# ICSSM0_COMMON_0_RAT_SLICE0_CFG register map
Vendor: Texas Instruments
Peripheral module from a debugger description file (folder am62x).
Registers are 32-bit, read-only, reset 0x0 unless marked. A register's access mark holds for its fields unless they carry their own. Offsets are as the file gives them; lines under a group give offsets from that group; [hi:lo] are bit positions; {n}, {i} and the like mark numbered series; 'fields as' and 'values as' point back to an identical list; <NAME> marks a mode.

## ICSSM0_COMMON_0_RAT_SLICE0_CFG
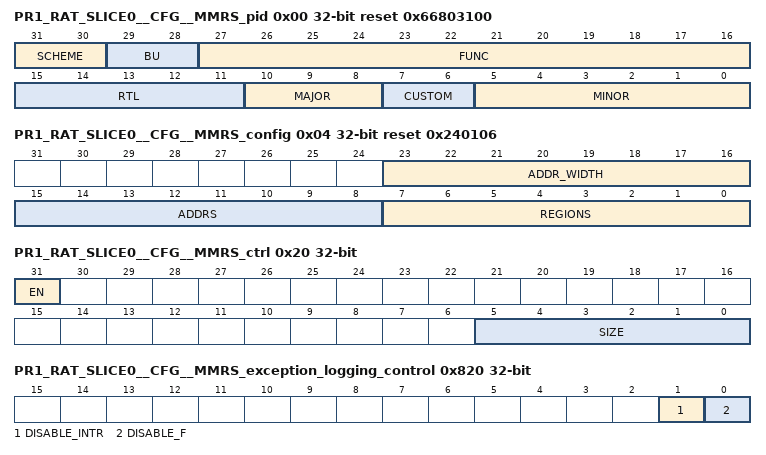
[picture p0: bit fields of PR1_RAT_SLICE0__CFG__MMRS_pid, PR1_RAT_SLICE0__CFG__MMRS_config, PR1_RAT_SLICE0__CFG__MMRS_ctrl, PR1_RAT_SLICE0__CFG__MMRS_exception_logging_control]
0x00 PR1_RAT_SLICE0__CFG__MMRS_pid reset 0x66803100
  [31:30] SCHEME — PID register scheme
  [29:28] BU — Business Unit: 10 = Processors
  [27:16] FUNC — Module ID
  [15:11] RTL — RTL revision. Will vary depending on release.
  [10:8] MAJOR — Major revision
  [7:6] CUSTOM
  [5:0] MINOR — Minor revision
0x04 PR1_RAT_SLICE0__CFG__MMRS_config reset 0x240106
  [23:16] ADDR_WIDTH — Number of address bits
  [15:8] ADDRS — Number of addresses
  [7:0] REGIONS — Number of regions
0x20 PR1_RAT_SLICE0__CFG__MMRS_ctrl rw
  [31] EN — Enable for the Region
  [5:0] SIZE — Size of the Region in Address Bits. 0 = 1 byte, 1 = 2B, 2 = 4B, 3 = 8B, etc. up to 32 = 4GB.
0x24 PR1_RAT_SLICE0__CFG__MMRS_base rw
  [31:0] BASE — Base Address for the Region. It must be aligned to the programmed size.
0x28 PR1_RAT_SLICE0__CFG__MMRS_trans_l rw
  [31:0] LOWER — Translated Lower Address Bits for the Region. It must be aligned to the programmed size.
0x2C PR1_RAT_SLICE0__CFG__MMRS_trans_u rw
  [3:0] UPPER — Translated Upper Address Bits for the Region
0x804 PR1_RAT_SLICE0__CFG__MMRS_destination_id rw
  [7:0] DEST_ID — The destination ID.
0x820 PR1_RAT_SLICE0__CFG__MMRS_exception_logging_control rw
  [1] DISABLE_INTR — Disables logging interrupt when set.
  [0] DISABLE_F — Disables logging when set.
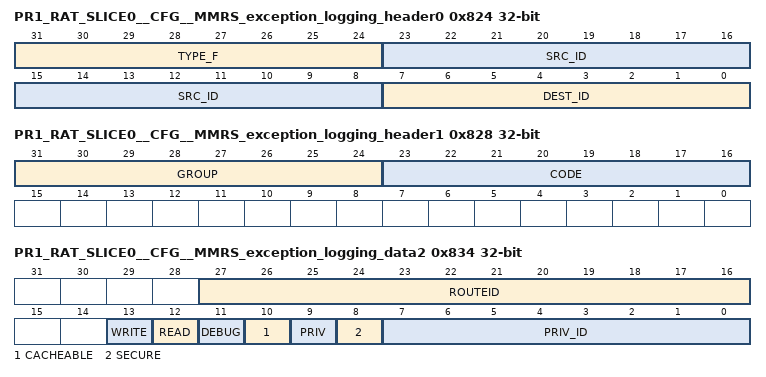
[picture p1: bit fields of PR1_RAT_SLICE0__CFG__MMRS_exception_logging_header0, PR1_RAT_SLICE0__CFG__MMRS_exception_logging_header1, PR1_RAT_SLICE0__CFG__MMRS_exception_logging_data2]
0x824 PR1_RAT_SLICE0__CFG__MMRS_exception_logging_header0
  [31:24] TYPE_F — Type. 4 = RAT.
  [23:8] SRC_ID — Source ID.
  [7:0] DEST_ID — Destination ID.
0x828 PR1_RAT_SLICE0__CFG__MMRS_exception_logging_header1
  [31:24] GROUP
  [23:16] CODE — Code. 1 = Boundary crossing error.
0x82C PR1_RAT_SLICE0__CFG__MMRS_exception_logging_data0
  [31:0] ADDR_L — Address lower 32 bits.
0x830 PR1_RAT_SLICE0__CFG__MMRS_exception_logging_data1
  [15:0] ADDR_H — Address upper 12 bits.
0x834 PR1_RAT_SLICE0__CFG__MMRS_exception_logging_data2
  [27:16] ROUTEID, [13] WRITE, [12] READ, [11] DEBUG, [10] CACHEABLE, [9] PRIV, [8] SECURE, [7:0] PRIV_ID
0x838 PR1_RAT_SLICE0__CFG__MMRS_exception_logging_data3
  [9:0] BYTECNT — Byte count.
0x840 PR1_RAT_SLICE0__CFG__MMRS_exception_pend_set access not given
  [0] PEND_SET — Write a 1 to set the exception pend signal. (access R/W1TS)
0x844 PR1_RAT_SLICE0__CFG__MMRS_exception_pend_clear access not given
  [0] PEND_CLR — Write a 1 to clear the exception pend signal. (access R/W1TC)
0x848 PR1_RAT_SLICE0__CFG__MMRS_exception_enable_set access not given
  [0] ENABLE_SET — Write a 1 to set the exception interrupt enable signal. (access R/W1TS)
0x84C PR1_RAT_SLICE0__CFG__MMRS_exception_enable_clear access not given
  [0] ENABLE_CLR — Write a 1 to clear the exception interrupt enable signal. (access R/W1TC)
0x850 PR1_RAT_SLICE0__CFG__MMRS_eoi_reg rw
  [15:0] EOI_WR — EOI Register
